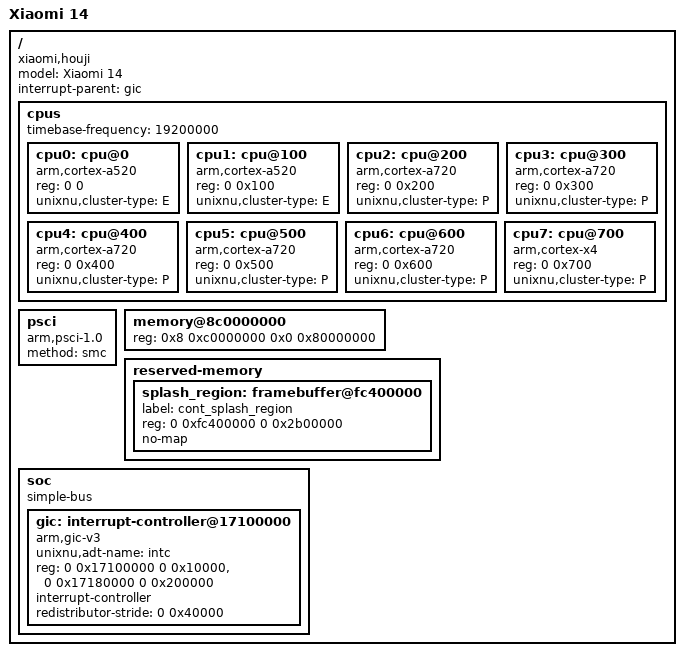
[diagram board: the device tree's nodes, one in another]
// SPDX-License-Identifier: BSD-3-Clause
// Xiaomi 14 (houji), SM8650. CPU affinities, GIC ranges and the timer frequency are the values the iOS 16 port of this phone
// runs with; the memory window and the framebuffer are from this phone's UEFI memory map.
/dts-v1/;

/ {
    model = "Xiaomi 14";
    compatible = "xiaomi,houji", "qcom,sm8650";
    #address-cells = <2>;
    #size-cells = <2>;
    interrupt-parent = <&gic>;

    cpus {
        #address-cells = <2>;
        #size-cells = <0>;
        timebase-frequency = <19200000>;
        cpu0: cpu@0 { device_type = "cpu"; compatible = "arm,cortex-a520"; reg = <0 0>; unixnu,cluster-type = "E"; };
        cpu1: cpu@100 { device_type = "cpu"; compatible = "arm,cortex-a520"; reg = <0 0x100>; unixnu,cluster-type = "E"; };
        cpu2: cpu@200 { device_type = "cpu"; compatible = "arm,cortex-a720"; reg = <0 0x200>; unixnu,cluster-type = "P"; };
        cpu3: cpu@300 { device_type = "cpu"; compatible = "arm,cortex-a720"; reg = <0 0x300>; unixnu,cluster-type = "P"; };
        cpu4: cpu@400 { device_type = "cpu"; compatible = "arm,cortex-a720"; reg = <0 0x400>; unixnu,cluster-type = "P"; };
        cpu5: cpu@500 { device_type = "cpu"; compatible = "arm,cortex-a720"; reg = <0 0x500>; unixnu,cluster-type = "P"; };
        cpu6: cpu@600 { device_type = "cpu"; compatible = "arm,cortex-a720"; reg = <0 0x600>; unixnu,cluster-type = "P"; };
        cpu7: cpu@700 { device_type = "cpu"; compatible = "arm,cortex-x4"; reg = <0 0x700>; unixnu,cluster-type = "P"; };
    };

    psci { compatible = "arm,psci-1.0"; method = "smc"; };

    // The high RAM range of the firmware memory map (0x8C0000000 to 0xBEA400000); the first 2 GiB are the contiguous handoff range.
    memory@8c0000000 {
        device_type = "memory";
        reg = <0x8 0xc0000000 0x0 0x80000000>;
    };

    reserved-memory {
        #address-cells = <2>;
        #size-cells = <2>;
        ranges;
        splash_region: framebuffer@fc400000 {
            label = "cont_splash_region";
            reg = <0 0xfc400000 0 0x2b00000>;
            no-map;
        };
    };

    soc {
        compatible = "simple-bus";
        #address-cells = <2>;
        #size-cells = <2>;
        ranges;

        gic: interrupt-controller@17100000 {
            compatible = "arm,gic-v3";
            unixnu,adt-name = "intc";
            reg = <0 0x17100000 0 0x10000>, <0 0x17180000 0 0x200000>;
            #interrupt-cells = <4>;
            #address-cells = <0>;
            interrupt-controller;
            redistributor-stride = <0 0x40000>;
        };
    };
};
